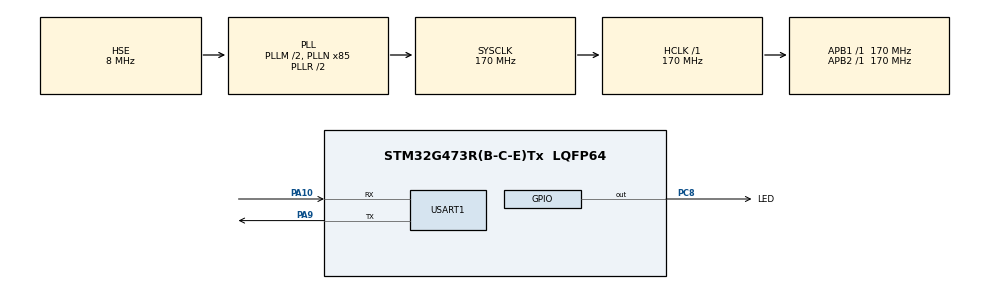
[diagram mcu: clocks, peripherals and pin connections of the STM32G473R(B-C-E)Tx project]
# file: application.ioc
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Mcu.Family=STM32G4
Mcu.Name=STM32G473R(B-C-E)Tx
Mcu.Package=LQFP64
NVIC.PriorityGroup=NVIC_PRIORITYGROUP_4
PA10.GPIO_PuPd=GPIO_PULLUP
PA10.Mode=Asynchronous
PA10.Signal=USART1_RX
PA13.Mode=Serial_Wire
PA13.Signal=SYS_JTMS-SWDIO
PA14.Mode=Serial_Wire
PA14.Signal=SYS_JTCK-SWCLK
PA9.GPIO_PuPd=GPIO_PULLUP
PA9.Mode=Asynchronous
PA9.Signal=USART1_TX
PC8.GPIO_Label=LED
PC8.GPIO_PuPd=GPIO_PULLUP
PC8.PinState=GPIO_PIN_SET
PC8.Signal=GPIO_Output
PF0-OSC_IN.Mode=HSE-External-Oscillator
PF0-OSC_IN.Signal=RCC_OSC_IN
PF1-OSC_OUT.Mode=HSE-External-Oscillator
PF1-OSC_OUT.Signal=RCC_OSC_OUT
ProjectManager.HeapSize=0x200
ProjectManager.StackSize=0x400
ProjectManager.TargetToolchain=MDK-ARM V5.32
RCC.ADC12Freq_Value=170000000
RCC.ADC345Freq_Value=170000000
RCC.AHBFreq_Value=170000000
RCC.APB1Freq_Value=170000000
RCC.APB1TimFreq_Value=170000000
RCC.APB2Freq_Value=170000000
RCC.APB2TimFreq_Value=170000000
RCC.CortexFreq_Value=170000000
RCC.EXTERNAL_CLOCK_VALUE=12288000
RCC.HCLKFreq_Value=170000000
RCC.HSE_VALUE=8000000
RCC.HSI48_VALUE=48000000
RCC.HSI_VALUE=16000000
RCC.LSE_VALUE=32768
RCC.PLLM=RCC_PLLM_DIV2
RCC.PLLN=85
RCC.PLLSourceVirtual=RCC_PLLSOURCE_HSE
RCC.SYSCLKFreq_VALUE=170000000
RCC.SYSCLKSource=RCC_SYSCLKSOURCE_PLLCLK
RCC.USBFreq_Value=170000000
RCC.VCOOutputFreq_Value=340000000
USART1.Parity=PARITY_NONE
USART1.VirtualMode-Asynchronous=VM_ASYNC
VP_SYS_VS_DBSignals.Mode=DisableDeadBatterySignals
board=custom

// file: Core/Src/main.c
/* USER CODE BEGIN Header */
/**
  ******************************************************************************
  * @file           : main.c
  * @brief          : Main program body
  ******************************************************************************
  * @attention
  *
  * Copyright (c) 2023 STMicroelectronics.
  * All rights reserved.
  *
  * This software is licensed under terms that can be found in the LICENSE file
  * in the root directory of this software component.
  * If no LICENSE file comes with this software, it is provided AS-IS.
  *
  ******************************************************************************
  */

	/* How to use:
	 * 	1. app USART1 config: 115200,8,N,1; LED flash at 1Hz;
	 * 	2. MCU receive 0x5A from usart1_rx(PA10), then jump to ROM bootloader;
	 * 	3. stm32cubeprogrammer config: 115200,8,Even,1; and connect to usart1;
	 *  4. open firmware and download, then power on reset the MCU;
	 */

/* USER CODE END Header */
#include "main.h"
#include "usart.h"
#include "gpio.h"

/* USER CODE BEGIN Includes */
#include "string.h"
#include "stdio.h"
/* USER CODE END Includes */

/* USER CODE BEGIN PTD */
typedef void (*pFunction)(void);
/* USER CODE END PTD */

/* USER CODE BEGIN PD */
#define BUF_LEN	256

#define BOOTLOADER_FLAG_VALUE 			0xDEADBEEF
#define BOOTLOADER_FLAG_OFFSET 			0x50
#define BOOTLOADER_ADDRESS					(0x1FFF0000)		// refer AN2606 rev.59 P234
/* USER CODE END PD */

/* USER CODE BEGIN PV */
static uint8_t* txBuf[BUF_LEN];
static uint8_t rxBuf;

uint32_t endstack = 0x20020000;		// RAM size: 128KB
uint32_t *bootloader_flag;
uint32_t JumpAddress;
pFunction JumpToApplication;
/* USER CODE END PV */

void SystemClock_Config(void);

int main(void)
{
  /* USER CODE BEGIN 1 */
	bootloader_flag = (uint32_t*)(endstack - BOOTLOADER_FLAG_OFFSET);

	if(*bootloader_flag == BOOTLOADER_FLAG_VALUE) {
		*bootloader_flag = 0;

		// Jump to system memory(ROM) bootloader
		__HAL_SYSCFG_REMAPMEMORY_SYSTEMFLASH();			// remap system memory to 0x00000000
		JumpAddress = *(__IO uint32_t*)(BOOTLOADER_ADDRESS + 4);
		JumpToApplication = (pFunction)JumpAddress;
		__set_MSP(*(__IO uint32_t*)BOOTLOADER_ADDRESS);
		JumpToApplication();
	}
	*bootloader_flag = 0;
  /* USER CODE END 1 */

  /* MCU Configuration--------------------------------------------------------*/

  /* Reset of all peripherals, Initializes the Flash interface and the Systick. */
  HAL_Init();

  /* Configure the system clock */
  SystemClock_Config();

  /* Initialize all configured peripherals */
  MX_GPIO_Init();
  MX_USART1_UART_Init();
  /* USER CODE BEGIN 2 */
	sprintf((char*)txBuf, "stm32g473rc firmware update by ROM demo...\r\n");
	HAL_UART_Transmit(&huart1, (const uint8_t*)txBuf, strlen((const char*)txBuf), 100);
  /* USER CODE END 2 */

  /* Infinite loop */
  /* USER CODE BEGIN WHILE */
	uint32_t now, then = 0;
  while (1)
  {
		now = HAL_GetTick();
		if(now - then >= 500) {
			then = now;
			HAL_GPIO_TogglePin(LED_GPIO_Port, LED_Pin);
		}

		HAL_UART_Receive(&huart1, &rxBuf, 1, 100);
		if(rxBuf == 0x5A) {
			sprintf((char*)txBuf, "Jump to ROM bootloader...\r\n");
			HAL_UART_Transmit(&huart1, (const uint8_t*)txBuf, strlen((const char*)txBuf), 100);
			__disable_irq();
			*bootloader_flag = BOOTLOADER_FLAG_VALUE;
			HAL_NVIC_SystemReset();
		}
    /* USER CODE END WHILE */

  }
}

void SystemClock_Config(void)
{
  RCC_OscInitTypeDef RCC_OscInitStruct = {0};
  RCC_ClkInitTypeDef RCC_ClkInitStruct = {0};

  /** Configure the main internal regulator output voltage
  */
  HAL_PWREx_ControlVoltageScaling(PWR_REGULATOR_VOLTAGE_SCALE1_BOOST);

  /** Initializes the RCC Oscillators according to the specified parameters
  * in the RCC_OscInitTypeDef structure.
  */
  RCC_OscInitStruct.OscillatorType = RCC_OSCILLATORTYPE_HSE;
  RCC_OscInitStruct.HSEState = RCC_HSE_ON;
  RCC_OscInitStruct.PLL.PLLState = RCC_PLL_ON;
  RCC_OscInitStruct.PLL.PLLSource = RCC_PLLSOURCE_HSE;
  RCC_OscInitStruct.PLL.PLLM = RCC_PLLM_DIV2;
  RCC_OscInitStruct.PLL.PLLN = 85;
  RCC_OscInitStruct.PLL.PLLP = RCC_PLLP_DIV2;
  RCC_OscInitStruct.PLL.PLLQ = RCC_PLLQ_DIV2;
  RCC_OscInitStruct.PLL.PLLR = RCC_PLLR_DIV2;
  if (HAL_RCC_OscConfig(&RCC_OscInitStruct) != HAL_OK)
  {
    Error_Handler();
  }

  /** Initializes the CPU, AHB and APB buses clocks
  */
  RCC_ClkInitStruct.ClockType = RCC_CLOCKTYPE_HCLK|RCC_CLOCKTYPE_SYSCLK
                              |RCC_CLOCKTYPE_PCLK1|RCC_CLOCKTYPE_PCLK2;
  RCC_ClkInitStruct.SYSCLKSource = RCC_SYSCLKSOURCE_PLLCLK;
  RCC_ClkInitStruct.AHBCLKDivider = RCC_SYSCLK_DIV1;
  RCC_ClkInitStruct.APB1CLKDivider = RCC_HCLK_DIV1;
  RCC_ClkInitStruct.APB2CLKDivider = RCC_HCLK_DIV1;

  if (HAL_RCC_ClockConfig(&RCC_ClkInitStruct, FLASH_LATENCY_4) != HAL_OK)
  {
    Error_Handler();
  }
}

void Error_Handler(void)
{
  __disable_irq();
  while (1)
  {
  }
}
